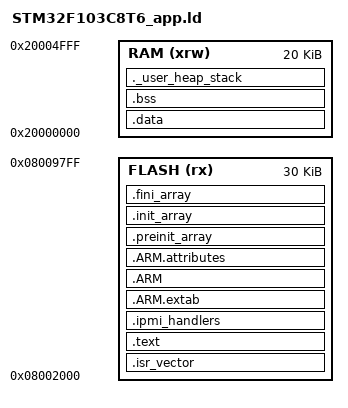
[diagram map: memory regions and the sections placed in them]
/*
*****************************************************************************
**
**  File        : stm32_flash.ld
**
**  Abstract    : Linker script for STM32F103CXT6 Device with
**                64/128KByte FLASH, 20KByte RAM
**
**                Set heap size, stack size and stack location according
**                to application requirements.
**
**                Set memory bank area and size if external memory is used.
**
**  Target      : STMicroelectronics STM32
**
**  Environment : GNU
**
**  Distribution: The file is distributed as is, without any warranty
**                of any kind.
**
**  You may use this file as-is or modify it according to the needs of your
**  project. Distribution of this file (unmodified or modified) is not
**  permitted. Atollic AB permit registered Atollic TrueSTUDIO(R) users the
**  rights to distribute the assembled, compiled & linked contents of this
**  file as part of an application binary file, provided that it is built
**  using the Atollic TrueSTUDIO(R) toolchain.
**
*****************************************************************************
*/

/* Entry Point */
ENTRY(Reset_Handler)

/* Highest address of the user mode stack */
_estack = 0x20005000;    /* end of 20K RAM */

/* Generate a link error if heap and stack don't fit into RAM */
_Min_Heap_Size  = 1K;    /* required amount of heap  */
_Min_Stack_Size = 512;    /* required amount of stack */

/* Specify the memory areas */
MEMORY
{
  FLASH (rx)      : ORIGIN = 0x08002000, LENGTH = 30K
  RAM (xrw)       : ORIGIN = 0x20000000, LENGTH = 20K
}

__BootFlash_start     = 0x08000000;   /* Bootloader start address (vector table) */
__BootFlash_end       = 0x08001FFF;   /* Bootloader end address (last byte) */
__AppFlash_start      = 0x08002000;   /* Application start address (vector table) */
__AppFlash_end        = 0x08006FFF;   /* 28K Application end address (last byte) */
__FWUpdateFlash_start = 0x08007000;   /* Firmware update region start address */
__FWUpdateFlash_end   = 0x0800FFFF;   /* 28K Firmware update region end address (last byte) */
__FWInfo_addr         = __FWUpdateFlash_end - 255; /* Last 256 bytes of flash reserved to the fw_info struct */

/* Define output sections */
SECTIONS
{
  /* The startup code goes first into FLASH */
  .isr_vector :
  {
    . = ALIGN(4);
    KEEP(*(.isr_vector)) /* Startup code */
    . = ALIGN(4);
  } >FLASH

  /* The program code and other data goes into FLASH */
  .text :
  {
    . = ALIGN(4);
    *(.text)           /* .text sections (code) */
    *(.text*)          /* .text* sections (code) */
    *(.rodata)         /* .rodata sections (constants, strings, etc.) */
    *(.rodata*)        /* .rodata* sections (constants, strings, etc.) */
    *(.glue_7)         /* glue arm to thumb code */
    *(.glue_7t)        /* glue thumb to arm code */

    KEEP (*(.init))
    KEEP (*(.fini))

    . = ALIGN(4);
    _etext = .;        /* define a global symbols at end of code */
  } >FLASH

  .ipmi_handlers : ALIGN(32)
  {
      _ipmi_handlers = .;
      KEEP(*(.ipmi_handlers))
      _eipmi_handlers = .;
  } > FLASH

   .ARM.extab   : { *(.ARM.extab* .gnu.linkonce.armextab.*) } >FLASH
    .ARM : {
    __exidx_start = .;
      *(.ARM.exidx*)
      __exidx_end = .;
    } >FLASH

  .ARM.attributes : { *(.ARM.attributes) } > FLASH

  .preinit_array     :
  {
    PROVIDE_HIDDEN (__preinit_array_start = .);
    KEEP (*(.preinit_array*))
    PROVIDE_HIDDEN (__preinit_array_end = .);
  } >FLASH
  .init_array :
  {
    PROVIDE_HIDDEN (__init_array_start = .);
    KEEP (*(SORT(.init_array.*)))
    KEEP (*(.init_array*))
    PROVIDE_HIDDEN (__init_array_end = .);
  } >FLASH
  .fini_array :
  {
    PROVIDE_HIDDEN (__fini_array_start = .);
    KEEP (*(.fini_array*))
    KEEP (*(SORT(.fini_array.*)))
    PROVIDE_HIDDEN (__fini_array_end = .);
  } >FLASH

  /* used by the startup to initialize data */
  _sidata = .;

  /* Initialized data sections goes into RAM, load LMA copy after code */
  .data : AT ( _sidata )
  {
    . = ALIGN(4);
    _sdata = .;        /* create a global symbol at data start */
    *(.ramfunc)        /* .RamFunc sections */
    *(.ramfunc*)       /* .RamFunc* sections */
    *(.data)           /* .data sections */
    *(.data*)          /* .data* sections */

    . = ALIGN(4);
    _edata = .;        /* define a global symbol at data end */
  } >RAM

  /* Uninitialized data section */
  . = ALIGN(4);
  .bss :
  {
    /* This is used by the startup in order to initialize the .bss secion */
    _sbss = .;         /* define a global symbol at bss start */
    __bss_start__ = _sbss;
    *(.bss)
    *(.bss*)
    *(COMMON)

    . = ALIGN(4);
    _ebss = .;         /* define a global symbol at bss end */
    __bss_end__ = _ebss;
  } >RAM

  PROVIDE ( end = _ebss );
  PROVIDE ( _end = _ebss );

  /* User_heap_stack section, used to check that there is enough RAM left */
  ._user_heap_stack :
  {
    . = ALIGN(4);
    . = . + _Min_Heap_Size;
    . = . + _Min_Stack_Size;
    . = ALIGN(4);
  } >RAM

  /* Remove information from the standard libraries */
  /DISCARD/ :
  {
    libc.a ( * )
    libm.a ( * )
    libgcc.a ( * )
  }
}
